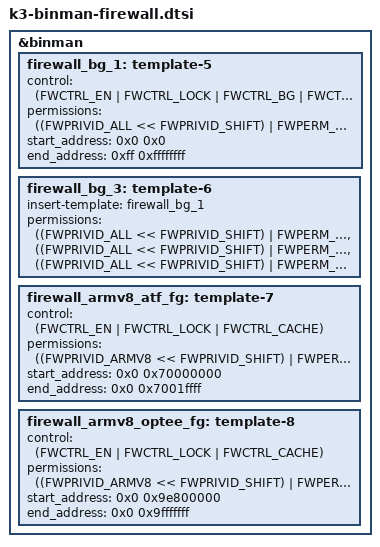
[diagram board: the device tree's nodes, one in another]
// SPDX-License-Identifier: GPL-2.0
/*
 * Copyright (C) 2022-2025 Texas Instruments Incorporated - https://www.ti.com/
 *
 * Firewall configuration templates for K3 SoC binman images.
 * These templates define firewall regions for ATF, OP-TEE, and background
 * memory regions used during secure boot.
 */

#include "k3-security.h"

&binman {
	firewall_bg_1: template-5 {
		control = <(FWCTRL_EN | FWCTRL_LOCK |
					FWCTRL_BG | FWCTRL_CACHE)>;
		permissions = <((FWPRIVID_ALL << FWPRIVID_SHIFT) |
						FWPERM_SECURE_PRIV_RWCD |
						FWPERM_SECURE_USER_RWCD |
						FWPERM_NON_SECURE_PRIV_RWCD |
						FWPERM_NON_SECURE_USER_RWCD)>;
		start_address = <0x0 0x0>;
		end_address = <0xff 0xffffffff>;
	};
	firewall_bg_3: template-6 {
		insert-template = <&firewall_bg_1>;
		permissions = <((FWPRIVID_ALL << FWPRIVID_SHIFT) |
						FWPERM_SECURE_PRIV_RWCD |
						FWPERM_SECURE_USER_RWCD |
						FWPERM_NON_SECURE_PRIV_RWCD |
						FWPERM_NON_SECURE_USER_RWCD)>,
					  <((FWPRIVID_ALL << FWPRIVID_SHIFT) |
						FWPERM_SECURE_PRIV_RWCD |
						FWPERM_SECURE_USER_RWCD |
						FWPERM_NON_SECURE_PRIV_RWCD |
						FWPERM_NON_SECURE_USER_RWCD)>,
					  <((FWPRIVID_ALL << FWPRIVID_SHIFT) |
						FWPERM_SECURE_PRIV_RWCD |
						FWPERM_SECURE_USER_RWCD |
						FWPERM_NON_SECURE_PRIV_RWCD |
						FWPERM_NON_SECURE_USER_RWCD)>;
	};
	firewall_armv8_atf_fg: template-7 {
		control = <(FWCTRL_EN | FWCTRL_LOCK |
					FWCTRL_CACHE)>;
		permissions = <((FWPRIVID_ARMV8 << FWPRIVID_SHIFT) |
						FWPERM_SECURE_PRIV_RWCD |
						FWPERM_SECURE_USER_RWCD)>;
		start_address = <0x0 0x70000000>;
		end_address = <0x0 0x7001ffff>;
	};
	firewall_armv8_optee_fg: template-8 {
		control = <(FWCTRL_EN | FWCTRL_LOCK |
					FWCTRL_CACHE)>;
		permissions = <((FWPRIVID_ARMV8 << FWPRIVID_SHIFT) |
						FWPERM_SECURE_PRIV_RWCD |
						FWPERM_SECURE_USER_RWCD)>;
		start_address = <0x0 0x9e800000>;
		end_address = <0x0 0x9fffffff>;
	};
};
